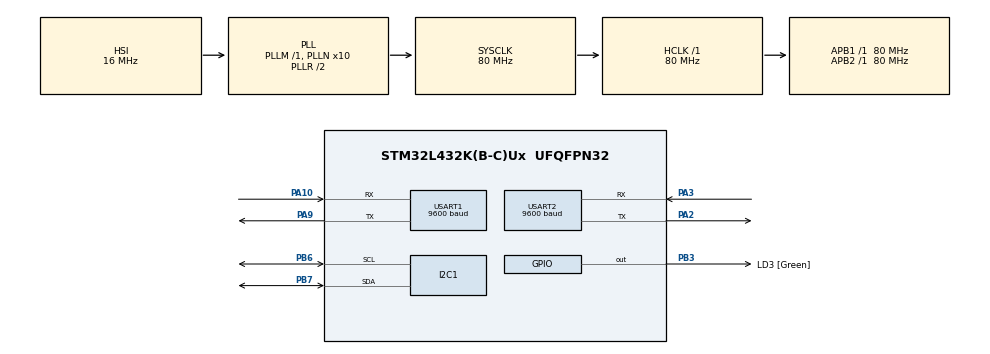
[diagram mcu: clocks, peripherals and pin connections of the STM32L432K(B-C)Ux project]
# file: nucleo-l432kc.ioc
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CRC.CRCLength=CRC_POLYLENGTH_16B
CRC.DefaultInitValueUse=DEFAULT_INIT_VALUE_ENABLE
CRC.DefaultPolynomialUse=DEFAULT_POLYNOMIAL_DISABLE
CRC.InputDataInversionMode=CRC_INPUTDATA_INVERSION_BYTE
CRC.OutputDataInversionMode=CRC_OUTPUTDATA_INVERSION_ENABLE
Dma.I2C1_TX.4.Direction=DMA_MEMORY_TO_PERIPH
Dma.I2C1_TX.4.Instance=DMA2_Channel7
Dma.I2C1_TX.4.MemDataAlignment=DMA_MDATAALIGN_BYTE
Dma.I2C1_TX.4.MemInc=DMA_MINC_ENABLE
Dma.I2C1_TX.4.Mode=DMA_NORMAL
Dma.I2C1_TX.4.PeriphDataAlignment=DMA_PDATAALIGN_BYTE
Dma.I2C1_TX.4.PeriphInc=DMA_PINC_DISABLE
Dma.I2C1_TX.4.Priority=DMA_PRIORITY_LOW
Dma.Request0=USART1_RX
Dma.Request1=USART1_TX
Dma.Request2=USART2_RX
Dma.Request3=USART2_TX
Dma.Request4=I2C1_TX
Dma.USART1_RX.0.Direction=DMA_PERIPH_TO_MEMORY
Dma.USART1_RX.0.Instance=DMA1_Channel5
Dma.USART1_RX.0.MemDataAlignment=DMA_MDATAALIGN_BYTE
Dma.USART1_RX.0.MemInc=DMA_MINC_ENABLE
Dma.USART1_RX.0.Mode=DMA_NORMAL
Dma.USART1_RX.0.PeriphDataAlignment=DMA_PDATAALIGN_BYTE
Dma.USART1_RX.0.PeriphInc=DMA_PINC_DISABLE
Dma.USART1_RX.0.Priority=DMA_PRIORITY_HIGH
Dma.USART1_TX.1.Direction=DMA_MEMORY_TO_PERIPH
Dma.USART1_TX.1.Instance=DMA1_Channel4
Dma.USART1_TX.1.MemDataAlignment=DMA_MDATAALIGN_BYTE
Dma.USART1_TX.1.MemInc=DMA_MINC_ENABLE
Dma.USART1_TX.1.Mode=DMA_NORMAL
Dma.USART1_TX.1.PeriphDataAlignment=DMA_PDATAALIGN_BYTE
Dma.USART1_TX.1.PeriphInc=DMA_PINC_DISABLE
Dma.USART1_TX.1.Priority=DMA_PRIORITY_HIGH
Dma.USART2_RX.2.Direction=DMA_PERIPH_TO_MEMORY
Dma.USART2_RX.2.Instance=DMA1_Channel6
Dma.USART2_RX.2.MemDataAlignment=DMA_MDATAALIGN_BYTE
Dma.USART2_RX.2.MemInc=DMA_MINC_ENABLE
Dma.USART2_RX.2.Mode=DMA_NORMAL
Dma.USART2_RX.2.PeriphDataAlignment=DMA_PDATAALIGN_BYTE
Dma.USART2_RX.2.PeriphInc=DMA_PINC_DISABLE
Dma.USART2_RX.2.Priority=DMA_PRIORITY_LOW
Dma.USART2_TX.3.Direction=DMA_MEMORY_TO_PERIPH
Dma.USART2_TX.3.Instance=DMA1_Channel7
Dma.USART2_TX.3.MemDataAlignment=DMA_MDATAALIGN_BYTE
Dma.USART2_TX.3.MemInc=DMA_MINC_ENABLE
Dma.USART2_TX.3.Mode=DMA_NORMAL
Dma.USART2_TX.3.PeriphDataAlignment=DMA_PDATAALIGN_BYTE
Dma.USART2_TX.3.PeriphInc=DMA_PINC_DISABLE
Dma.USART2_TX.3.Priority=DMA_PRIORITY_LOW
I2C1.Timing=0x10909CEC
Mcu.Family=STM32L4
Mcu.Name=STM32L432K(B-C)Ux
Mcu.Package=UFQFPN32
NVIC.DMA1_Channel4_IRQn=true\:0\:0\:false\:false\:true\:false\:true\:true
NVIC.DMA1_Channel5_IRQn=true\:0\:0\:false\:false\:true\:false\:true\:true
NVIC.DMA1_Channel6_IRQn=true\:0\:0\:false\:false\:true\:false\:true\:true
NVIC.DMA1_Channel7_IRQn=true\:0\:0\:false\:false\:true\:false\:true\:true
NVIC.DMA2_Channel7_IRQn=true\:0\:0\:false\:false\:true\:false\:true\:true
NVIC.I2C1_EV_IRQn=true\:0\:0\:false\:false\:true\:true\:true\:true
NVIC.PriorityGroup=NVIC_PRIORITYGROUP_4
NVIC.USART1_IRQn=true\:0\:0\:false\:false\:true\:true\:true\:true
NVIC.USART2_IRQn=true\:1\:0\:true\:false\:true\:true\:true\:true
PA0.Mode=HSE-External-Clock-Source-for-LittleOrca
PA0.Signal=RCC_CK_IN
PA10.GPIO_FM7=I2C_FASTMODEPLUS_PB7
PA10.Mode=Asynchronous
PA10.Signal=USART1_RX
PA13\ (JTMS-SWDIO).GPIO_Label=SWDIO
PA13\ (JTMS-SWDIO).Mode=Serial_Wire
PA13\ (JTMS-SWDIO).Signal=SYS_JTMS-SWDIO
PA14\ (JTCK-SWCLK).GPIO_Label=SWCLK
PA14\ (JTCK-SWCLK).Mode=Serial_Wire
PA14\ (JTCK-SWCLK).Signal=SYS_JTCK-SWCLK
PA2.Mode=Asynchronous
PA2.Signal=USART2_TX
PA3.Mode=Asynchronous
PA3.Signal=USART2_RX
PA9.GPIO_FM6=I2C_FASTMODEPLUS_PB6
PA9.Mode=Asynchronous
PA9.Signal=USART1_TX
PB3\ (JTDO-TRACESWO).GPIO_Label=LD3 [Green]
PB3\ (JTDO-TRACESWO).Signal=GPIO_Output
PB6.GPIO_Pu=GPIO_PULLUP
PB6.Mode=I2C
PB6.Signal=I2C1_SCL
PB7.GPIO_Pu=GPIO_PULLUP
PB7.Mode=I2C
PB7.Signal=I2C1_SDA
PC14-OSC32_IN\ (PC14).Mode=LSE-External-Oscillator
PC14-OSC32_IN\ (PC14).Signal=RCC_OSC32_IN
PC15-OSC32_OUT\ (PC15).Mode=LSE-External-Oscillator
PC15-OSC32_OUT\ (PC15).Signal=RCC_OSC32_OUT
ProjectManager.HeapSize=0x200
ProjectManager.StackSize=0x400
ProjectManager.TargetToolchain=STM32CubeIDE
RCC.ADCFreq_Value=64000000
RCC.AHBFreq_Value=80000000
RCC.APB1Freq_Value=80000000
RCC.APB1TimFreq_Value=80000000
RCC.APB2Freq_Value=80000000
RCC.APB2TimFreq_Value=80000000
RCC.CortexFreq_Value=80000000
RCC.HCLKFreq_Value=80000000
RCC.HSE_VALUE=8000000
RCC.HSI48_VALUE=48000000
RCC.HSI_VALUE=16000000
RCC.MSI_VALUE=4000000
RCC.PLLN=10
RCC.PLLSourceVirtual=RCC_PLLSOURCE_HSI
RCC.SYSCLKFreq_VALUE=80000000
RCC.SYSCLKSource=RCC_SYSCLKSOURCE_PLLCLK
RCC.USART2CLockSelection=RCC_USART2CLKSOURCE_SYSCLK
RCC.USBFreq_Value=64000000
RCC.VCOOutputFreq_Value=160000000
USART1.BaudRate=9600
USART1.OverSampling=UART_OVERSAMPLING_16
USART1.VirtualMode-Asynchronous=VM_ASYNC
USART2.BaudRate=9600
USART2.OverSampling=UART_OVERSAMPLING_16
USART2.VirtualMode-Asynchronous=VM_ASYNC
VP_CRC_VS_CRC.Mode=CRC_Activate
board=NUCLEO-L432KC

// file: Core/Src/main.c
/* USER CODE BEGIN Header */
/**
 ******************************************************************************
 * @file           : main.c
 * @brief          : Main program body
 ******************************************************************************
 * @attention
 *
 * Copyright (c) 2022 STMicroelectronics.
 * All rights reserved.
 *
 * This software is licensed under terms that can be found in the LICENSE file
 * in the root directory of this software component.
 * If no LICENSE file comes with this software, it is provided AS-IS.
 *
 ******************************************************************************
 */
/* USER CODE END Header */
#include "main.h"
#include "crc.h"
#include "dma.h"
#include "i2c.h"
#include "usart.h"
#include "gpio.h"

/* USER CODE BEGIN Includes */
#include "../../lib/bsp_mb_slave.h"
#include "test_lpuart.h"
#include "../../FM24W256/fm24w256.h"
#include <string.h>
/* USER CODE END Includes */

void SystemClock_Config(void);

/* USER CODE BEGIN 0 */
extern void modbus_slave_example_init(void);
extern void modbus_slave_example_run(void);
//static void test_i2c(void);
/* USER CODE END 0 */

int main(void)
{

  /* MCU Configuration--------------------------------------------------------*/

  /* Reset of all peripherals, Initializes the Flash interface and the Systick. */
  HAL_Init();

  /* Configure the system clock */
  SystemClock_Config();

  /* Initialize all configured peripherals */
  MX_GPIO_Init();
  MX_DMA_Init();
  MX_USART1_UART_Init();
  MX_CRC_Init();
  MX_USART2_UART_Init();
  MX_I2C1_Init();
  /* USER CODE BEGIN 2 */
//  modbus_slave_example_init();
  fm24w256_example();
  /* USER CODE END 2 */

  /* Infinite loop */
  /* USER CODE BEGIN WHILE */
	while (1)
	{
//		modbus_slave_example_run();

    /* USER CODE END WHILE */

	}
}

void SystemClock_Config(void)
{
  RCC_OscInitTypeDef RCC_OscInitStruct = {0};
  RCC_ClkInitTypeDef RCC_ClkInitStruct = {0};

  /** Configure the main internal regulator output voltage
  */
  if (HAL_PWREx_ControlVoltageScaling(PWR_REGULATOR_VOLTAGE_SCALE1) != HAL_OK)
  {
    Error_Handler();
  }

  /** Initializes the RCC Oscillators according to the specified parameters
  * in the RCC_OscInitTypeDef structure.
  */
  RCC_OscInitStruct.OscillatorType = RCC_OSCILLATORTYPE_HSI;
  RCC_OscInitStruct.HSIState = RCC_HSI_ON;
  RCC_OscInitStruct.HSICalibrationValue = RCC_HSICALIBRATION_DEFAULT;
  RCC_OscInitStruct.PLL.PLLState = RCC_PLL_ON;
  RCC_OscInitStruct.PLL.PLLSource = RCC_PLLSOURCE_HSI;
  RCC_OscInitStruct.PLL.PLLM = 1;
  RCC_OscInitStruct.PLL.PLLN = 10;
  RCC_OscInitStruct.PLL.PLLP = RCC_PLLP_DIV7;
  RCC_OscInitStruct.PLL.PLLQ = RCC_PLLQ_DIV2;
  RCC_OscInitStruct.PLL.PLLR = RCC_PLLR_DIV2;
  if (HAL_RCC_OscConfig(&RCC_OscInitStruct) != HAL_OK)
  {
    Error_Handler();
  }

  /** Initializes the CPU, AHB and APB buses clocks
  */
  RCC_ClkInitStruct.ClockType = RCC_CLOCKTYPE_HCLK|RCC_CLOCKTYPE_SYSCLK
                              |RCC_CLOCKTYPE_PCLK1|RCC_CLOCKTYPE_PCLK2;
  RCC_ClkInitStruct.SYSCLKSource = RCC_SYSCLKSOURCE_PLLCLK;
  RCC_ClkInitStruct.AHBCLKDivider = RCC_SYSCLK_DIV1;
  RCC_ClkInitStruct.APB1CLKDivider = RCC_HCLK_DIV1;
  RCC_ClkInitStruct.APB2CLKDivider = RCC_HCLK_DIV1;

  if (HAL_RCC_ClockConfig(&RCC_ClkInitStruct, FLASH_LATENCY_4) != HAL_OK)
  {
    Error_Handler();
  }
}

void Error_Handler(void)
{
	__disable_irq();
	while (1)
	{
	}
}
